AUTOSAR XML (schema 4-0-3)
standard types defined: UInt32, UInt8
package /AUTOSAR_Platform/DataConstrs
  range DC_UInt8: raw 0..255
package /PATAC/MSM/ComponentTypes
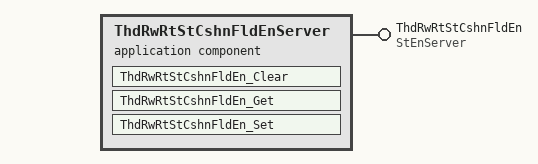
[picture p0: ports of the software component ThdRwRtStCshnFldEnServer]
  application sw component type ThdRwRtStCshnFldEnServer
    provide port ThdRwRtStCshnFldEn: provided-com-specs=[{operation=Clear, queue-length=1}, {operation=Get, queue-length=1}, {operation=Set, queue-length=1}], provided-interface=StEnServer
    behavior ThdRwRtStCshnFldEnServer_InternalBehavior
      operation invoked event OIT_ThdRwRtStCshnFldEn_Clear_ThdRwRtStCshnFldEn_Clear: start-on-event=ThdRwRtStCshnFldEn_Clear, operation=ThdRwRtStCshnFldEn.Clear
      operation invoked event OIT_ThdRwRtStCshnFldEn_Get_ThdRwRtStCshnFldEn_Get: start-on-event=ThdRwRtStCshnFldEn_Get, operation=ThdRwRtStCshnFldEn.Get
      operation invoked event OIT_ThdRwRtStCshnFldEn_Set_ThdRwRtStCshnFldEn_Set: start-on-event=ThdRwRtStCshnFldEn_Set, operation=ThdRwRtStCshnFldEn.Set
      runnable ThdRwRtStCshnFldEn_Clear
      runnable ThdRwRtStCshnFldEn_Get
      runnable ThdRwRtStCshnFldEn_Set
  swc implementation ThdRwRtStCshnFldEnServer_Implementation: behavior=ThdRwRtStCshnFldEnServer_InternalBehavior
    code-descriptors:
      code Default: artifact-descriptors=autosar-engineering-object={short-label=Default, category=SWSRC}
package /PATAC/MSM/ModeAdjust/PortInterface
  client server interface StEnServer
    operation Clear
      arg data: type=UInt8, direction=IN, server-argument-impl-policy=USE-ARGUMENT-TYPE
    operation Get
      arg data: type=UInt32, direction=OUT, server-argument-impl-policy=USE-ARGUMENT-TYPE
    operation Set
      arg data: type=UInt8, direction=IN, server-argument-impl-policy=USE-ARGUMENT-TYPE
